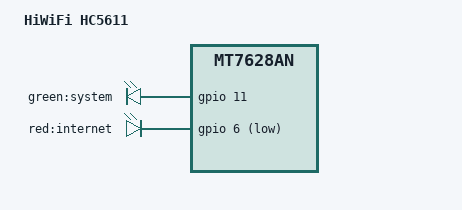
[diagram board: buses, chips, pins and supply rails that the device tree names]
// SPDX-License-Identifier: GPL-2.0-or-later OR MIT

#include "mt7628an_hiwifi_hc5x61a.dtsi"

/ {
	compatible = "hiwifi,hc5611", "mediatek,mt7628an-soc";
	model = "HiWiFi HC5611";

	leds {
		compatible = "gpio-leds";

		led_system: system {
			label = "green:system";
			gpios = <&gpio 11 GPIO_ACTIVE_HIGH>;
			default-state = "on";
		};

		internet {
			label = "red:internet";
			gpios = <&gpio 6 GPIO_ACTIVE_LOW>;
		};
	};
};

&state_default {
	gpio {
		groups = "gpio", "spi cs1", "wdt";
		function = "gpio";
	};
};
